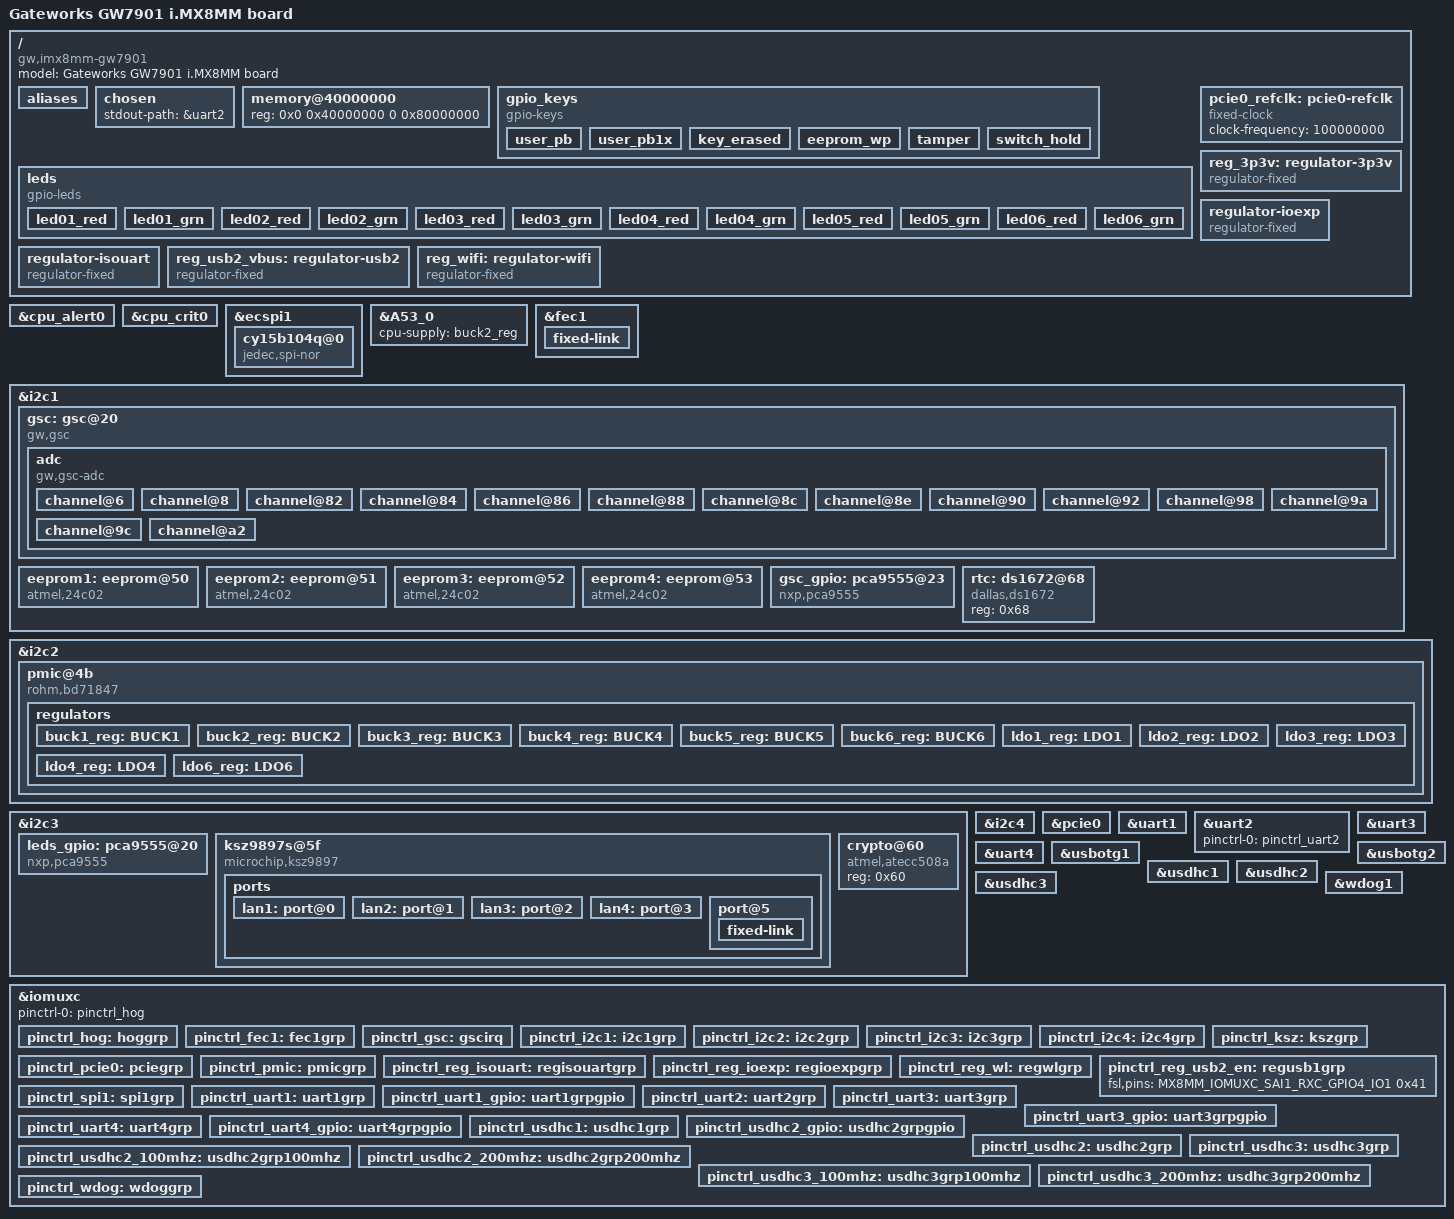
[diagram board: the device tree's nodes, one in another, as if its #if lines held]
// SPDX-License-Identifier: (GPL-2.0+ OR MIT)
/*
 * Copyright 2020 Gateworks Corporation
 */

/dts-v1/;

#include <dt-bindings/usb/pd.h>
#include <dt-bindings/input/linux-event-codes.h>
#include "imx8mm.dtsi"

/ {
	model = "Gateworks GW7901 i.MX8MM board";
	compatible = "gw,imx8mm-gw7901", "fsl,imx8mm";

	aliases {
		ethernet0 = &fec1;
		ethernet1 = &lan1;
		ethernet2 = &lan2;
		ethernet3 = &lan3;
		ethernet4 = &lan4;
		usb0 = &usbotg1;
		usb1 = &usbotg2;
	};

	chosen {
		stdout-path = &uart2;
	};

	memory@40000000 {
		device_type = "memory";
		reg = <0x0 0x40000000 0 0x80000000>;
	};

	gpio_keys {
		compatible = "gpio-keys";
		#address-cells = <1>;
		#size-cells = <0>;

		user_pb {
			label = "user_pb";
			gpios = <&gsc_gpio 2 GPIO_ACTIVE_LOW>;
			linux,code = <BTN_0>;
		};

		user_pb1x {
			label = "user_pb1x";
			linux,code = <BTN_1>;
			interrupt-parent = <&gsc>;
			interrupts = <0>;
		};

		key_erased {
			label = "key-erased";
			linux,code = <BTN_2>;
			interrupt-parent = <&gsc>;
			interrupts = <1>;
		};

		eeprom_wp {
			label = "eeprom_wp";
			linux,code = <BTN_3>;
			interrupt-parent = <&gsc>;
			interrupts = <2>;
		};

		tamper {
			label = "tamper";
			linux,code = <BTN_4>;
			interrupt-parent = <&gsc>;
			interrupts = <5>;
		};

		switch_hold {
			label = "switch_hold";
			linux,code = <BTN_5>;
			interrupt-parent = <&gsc>;
			interrupts = <7>;
		};
	};

	leds {
		compatible = "gpio-leds";

		led01_red {
			label = "led01_red";
			gpios = <&leds_gpio 0 GPIO_ACTIVE_HIGH>;
			default-state = "off";
		};

		led01_grn {
			label = "led01_grn";
			gpios = <&leds_gpio 1 GPIO_ACTIVE_HIGH>;
			default-state = "off";
		};

		led02_red {
			label = "led02_red";
			gpios = <&leds_gpio 2 GPIO_ACTIVE_HIGH>;
			default-state = "off";
		};

		led02_grn {
			label = "led02_grn";
			gpios = <&leds_gpio 3 GPIO_ACTIVE_HIGH>;
			default-state = "off";
		};

		led03_red {
			label = "led03_red";
			gpios = <&leds_gpio 4 GPIO_ACTIVE_HIGH>;
			default-state = "off";
		};

		led03_grn {
			label = "led03_grn";
			gpios = <&leds_gpio 5 GPIO_ACTIVE_HIGH>;
			default-state = "off";
		};

		led04_red {
			label = "led04_red";
			gpios = <&leds_gpio 8 GPIO_ACTIVE_HIGH>;
			default-state = "off";
		};

		led04_grn {
			label = "led04_grn";
			gpios = <&leds_gpio 9 GPIO_ACTIVE_HIGH>;
			default-state = "off";
		};

		led05_red {
			label = "led05_red";
			gpios = <&leds_gpio 10 GPIO_ACTIVE_HIGH>;
			default-state = "off";
		};

		led05_grn {
			label = "led05_grn";
			gpios = <&leds_gpio 11 GPIO_ACTIVE_HIGH>;
			default-state = "off";
		};

		led06_red {
			label = "led06_red";
			gpios = <&leds_gpio 12 GPIO_ACTIVE_HIGH>;
			default-state = "off";
		};

		led06_grn {
			label = "led06_grn";
			gpios = <&leds_gpio 13 GPIO_ACTIVE_HIGH>;
			default-state = "off";
		};
	};

	pcie0_refclk: pcie0-refclk {
		compatible = "fixed-clock";
		#clock-cells = <0>;
		clock-frequency = <100000000>;
	};

	reg_3p3v: regulator-3p3v {
		compatible = "regulator-fixed";
		regulator-name = "3P3V";
		regulator-min-microvolt = <3300000>;
		regulator-max-microvolt = <3300000>;
		regulator-always-on;
	};

	regulator-ioexp {
		pinctrl-names = "default";
		pinctrl-0 = <&pinctrl_reg_ioexp>;
		compatible = "regulator-fixed";
		regulator-name = "ioexp";
		gpio = <&gpio4 21 GPIO_ACTIVE_HIGH>;
		startup-delay-us = <100>;
		enable-active-high;
		regulator-min-microvolt = <3300000>;
		regulator-max-microvolt = <3300000>;
		regulator-always-on;
	};

	regulator-isouart {
		pinctrl-names = "default";
		pinctrl-0 = <&pinctrl_reg_isouart>;
		compatible = "regulator-fixed";
		regulator-name = "iso_uart";
		gpio = <&gpio1 13 GPIO_ACTIVE_LOW>;
		startup-delay-us = <100>;
		regulator-min-microvolt = <3300000>;
		regulator-max-microvolt = <3300000>;
		regulator-always-on;
	};

	reg_usb2_vbus: regulator-usb2 {
		pinctrl-names = "default";
		pinctrl-0 = <&pinctrl_reg_usb2_en>;
		compatible = "regulator-fixed";
		regulator-name = "usb_usb2_vbus";
		gpio = <&gpio4 1 GPIO_ACTIVE_HIGH>;
		enable-active-high;
		regulator-min-microvolt = <5000000>;
		regulator-max-microvolt = <5000000>;
	};

	reg_wifi: regulator-wifi {
		pinctrl-names = "default";
		pinctrl-0 = <&pinctrl_reg_wl>;
		compatible = "regulator-fixed";
		regulator-name = "wifi";
		gpio = <&gpio4 0 GPIO_ACTIVE_HIGH>;
		startup-delay-us = <100>;
		enable-active-high;
		regulator-min-microvolt = <3300000>;
		regulator-max-microvolt = <3300000>;
	};
};

&cpu_alert0 {
	temperature = <95000>;
	hysteresis = <2000>;
	type = "passive";
};

&cpu_crit0 {
	temperature = <105000>;
	hysteresis = <2000>;
	type = "critical";
};

&ecspi1 {
	pinctrl-names = "default";
	pinctrl-0 = <&pinctrl_spi1>;
	cs-gpios = <&gpio5 9 GPIO_ACTIVE_LOW>;
	status = "okay";

	/* CY15B104Q FRAM:
	 * requires adding to drivers/mtd/spi-nor/spi-nor.c:
	 * { "cy15x104q", INFO(0x7f7f7f, 0, 512 * 1024, 1, SPI_NOR_NO_ERASE) },
	 */
	cy15b104q@0 {
		compatible = "jedec,spi-nor", "cy15x104q";
		reg = <0>;
		spi-max-frequency = <40000000>;
		status = "okay";
	};
};

&A53_0 {
	cpu-supply = <&buck2_reg>;
};

&fec1 {
	pinctrl-names = "default";
	pinctrl-0 = <&pinctrl_fec1>;
	phy-mode = "rgmii-id";
	phy-reset-gpios = <&gpio4 19 GPIO_ACTIVE_LOW>;
	phy-reset-duration = <100>;
	phy-reset-post-delay = <100>;
	status = "okay";
	local-mac-address = [00 00 00 00 00 00];

	fixed-link {
		speed = <1000>;
		full-duplex;
	};
};

&i2c1 {
	clock-frequency = <100000>;
	pinctrl-names = "default";
	pinctrl-0 = <&pinctrl_i2c1>;
	status = "okay";

	gsc: gsc@20 {
		compatible = "gw,gsc";
		reg = <0x20>;
		pinctrl-0 = <&pinctrl_gsc>;
		interrupt-parent = <&gpio2>;
		interrupts = <6 IRQ_TYPE_EDGE_FALLING>;
		/*interrupts = <6 IRQ_TYPE_LEVEL_LOW>;*/
		interrupt-controller;
		#interrupt-cells = <1>;
		#size-cells = <0>;

		adc {
			compatible = "gw,gsc-adc";
			#address-cells = <1>;
			#size-cells = <0>;

			channel@6 {
				gw,mode = <0>;
				reg = <0x06>;
				label = "temp";
			};

			channel@8 {
				gw,mode = <1>;
				reg = <0x08>;
				label = "vdd_bat";
			};

			channel@82 {
				gw,mode = <2>;
				reg = <0x82>;
				label = "vin_aux1";
				gw,voltage-divider-ohms = <22100 1000>;
			};

			channel@84 {
				gw,mode = <2>;
				reg = <0x84>;
				label = "vin_aux2";
				gw,voltage-divider-ohms = <22100 1000>;
			};

			channel@86 {
				gw,mode = <2>;
				reg = <0x86>;
				label = "vdd_vin";
				gw,voltage-divider-ohms = <22100 1000>;
			};

			channel@88 {
				gw,mode = <2>;
				reg = <0x88>;
				label = "vdd_3p3";
				gw,voltage-divider-ohms = <10000 10000>;
			};

			channel@8c {
				gw,mode = <2>;
				reg = <0x8c>;
				label = "vdd_2p5";
				gw,voltage-divider-ohms = <10000 10000>;
			};

			channel@8e {
				gw,mode = <2>;
				reg = <0x8e>;
				label = "vdd_0p95";
			};

			channel@90 {
				gw,mode = <2>;
				reg = <0x90>;
				label = "vdd_soc";
			};

			channel@92 {
				gw,mode = <2>;
				reg = <0x92>;
				label = "vdd_arm";
			};

			channel@98 {
				gw,mode = <2>;
				reg = <0x98>;
				label = "vdd_1p8";
			};

			channel@9a {
				gw,mode = <2>;
				reg = <0x9a>;
				label = "vdd_1p2";
			};

			channel@9c {
				gw,mode = <2>;
				reg = <0x9c>;
				label = "vdd_dram";
			};

			channel@a2 {
				gw,mode = <2>;
				reg = <0xa2>;
				label = "vdd_gsc";
				gw,voltage-divider-ohms = <10000 10000>;
			};
		};
	};

	eeprom1: eeprom@50 {
		compatible = "atmel,24c02";
		reg = <0x50>;
		pagesize = <16>;
	};

	eeprom2: eeprom@51 {
		compatible = "atmel,24c02";
		reg = <0x51>;
		pagesize = <16>;
	};

	eeprom3: eeprom@52 {
		compatible = "atmel,24c02";
		reg = <0x52>;
		pagesize = <16>;
	};

	eeprom4: eeprom@53 {
		compatible = "atmel,24c02";
		reg = <0x53>;
		pagesize = <16>;
	};

	gsc_gpio: pca9555@23 {
		compatible = "nxp,pca9555";
		reg = <0x23>;
		gpio-controller;
		#gpio-cells = <2>;
		interrupt-parent = <&gsc>;
		interrupts = <4>;
	};

	rtc: ds1672@68 {
		compatible = "dallas,ds1672";
		reg = <0x68>;
	};
};

&i2c2 {
	clock-frequency = <400000>;
	pinctrl-names = "default";
	pinctrl-0 = <&pinctrl_i2c2>;
	status = "okay";

	pmic@4b {
		compatible = "rohm,bd71847";
		reg = <0x4b>;
		pinctrl-0 = <&pinctrl_pmic>;
		interrupt-parent = <&gpio3>;
		interrupts = <20 IRQ_TYPE_LEVEL_LOW>;

		regulators {
			/* VDD_SOC: 0.805-0.900V (typ=0.8V) */
			buck1_reg: BUCK1 {
				regulator-name = "BUCK1";
				regulator-min-microvolt = <700000>;
				regulator-max-microvolt = <1300000>;
				regulator-boot-on;
				regulator-always-on;
				regulator-ramp-delay = <1250>;
			};

			/* VDD_ARM: 0.805-1.0V (typ=0.9V) */
			buck2_reg: BUCK2 {
				regulator-name = "BUCK2";
				regulator-min-microvolt = <700000>;
				regulator-max-microvolt = <1300000>;
				regulator-boot-on;
				regulator-always-on;
				regulator-ramp-delay = <1250>;
				rohm,dvs-run-voltage = <1000000>;
				rohm,dvs-idle-voltage = <900000>;
			};

			/* VDD_0P95: 0.805-1.0V (typ=0.9V) */
			buck3_reg: BUCK3 {
				// BUCK5 in datasheet
				regulator-name = "BUCK3";
				regulator-min-microvolt = <700000>;
				regulator-max-microvolt = <1350000>;
				regulator-boot-on;
				regulator-always-on;
			};

			/* VDD_3P3 */
			buck4_reg: BUCK4 {
				// BUCK6 in datasheet
				regulator-name = "BUCK4";
				regulator-min-microvolt = <3000000>;
				regulator-max-microvolt = <3300000>;
				regulator-boot-on;
				regulator-always-on;
			};

			/* VDD_1P8 */
			buck5_reg: BUCK5 {
				// BUCK7 in datasheet
				regulator-name = "BUCK5";
				regulator-min-microvolt = <1605000>;
				regulator-max-microvolt = <1995000>;
				regulator-boot-on;
				regulator-always-on;
			};

			/* VDD_DRAM: typ=1.1V */
			buck6_reg: BUCK6 {
				// BUCK8 in datasheet
				regulator-name = "BUCK6";
				regulator-min-microvolt = <800000>;
				regulator-max-microvolt = <1400000>;
				regulator-boot-on;
				regulator-always-on;
			};

			/* NVCC_SNVS_1P8 */
			ldo1_reg: LDO1 {
				regulator-name = "LDO1";
				regulator-min-microvolt = <3000000>;
				regulator-max-microvolt = <3300000>;
				regulator-boot-on;
				regulator-always-on;
			};

			/* VDD_SNVS_0P8 */
			ldo2_reg: LDO2 {
				regulator-name = "LDO2";
				regulator-min-microvolt = <900000>;
				regulator-max-microvolt = <900000>;
				regulator-boot-on;
				regulator-always-on;
			};

			/* VDDA_1P8 */
			ldo3_reg: LDO3 {
				regulator-name = "LDO3";
				regulator-min-microvolt = <1800000>;
				regulator-max-microvolt = <3300000>;
				regulator-boot-on;
				regulator-always-on;
			};

			/* PMIC_LDO4 */
			ldo4_reg: LDO4 {
				regulator-name = "LDO4";
				regulator-min-microvolt = <900000>;
				regulator-max-microvolt = <1800000>;
				regulator-boot-on;
				regulator-always-on;
			};

			/* PMIC_LD06 */
			ldo6_reg: LDO6 {
				regulator-name = "LDO6";
				regulator-min-microvolt = <900000>;
				regulator-max-microvolt = <1800000>;
				regulator-boot-on;
				regulator-always-on;
			};
		};
	};
};

&i2c3 {
	clock-frequency = <400000>;
	pinctrl-names = "default";
	pinctrl-0 = <&pinctrl_i2c3>;
	status = "okay";

	leds_gpio: pca9555@20 {
		compatible = "nxp,pca9555";
		pinctrl-names = "default";
		reg = <0x20>;
		gpio-controller;
		#gpio-cells = <2>;
	};

	ksz9897s@5f {
		compatible = "microchip,ksz9897"; /* optional: ksz9477, ksz9567 */
		reg = <0x5f>;
		pinctrl-0 = <&pinctrl_ksz>;
		interrupt-parent = <&gpio4>;
		interrupts = <17 IRQ_TYPE_EDGE_FALLING>;
		phy-mode = "rgmii-id";

		ports {
			#address-cells = <1>;
			#size-cells = <0>;
			lan1: port@0 {
				reg = <0>;
				label = "lan1";
				local-mac-address = [00 00 00 00 00 00];
			};
			lan2: port@1 {
				reg = <1>;
				label = "lan2";
				local-mac-address = [00 00 00 00 00 00];
			};
			lan3: port@2 {
				reg = <2>;
				label = "lan3";
				local-mac-address = [00 00 00 00 00 00];
			};
			lan4: port@3 {
				reg = <3>;
				label = "lan4";
				local-mac-address = [00 00 00 00 00 00];
			};
			port@5 {
				reg = <5>;
				label = "cpu";
				ethernet = <&fec1>;
				phy-mode = "rgmii-id";

				fixed-link {
					speed = <1000>;
					full-duplex;
				};
			};
		};
	};

	/* is the ATECC608A compatible with the ATECC508 driver? */
	crypto@60 {
		compatible = "atmel,atecc508a";
		reg = <0x60>;
	};
};

&i2c4 {
	clock-frequency = <400000>;
	pinctrl-names = "default";
	pinctrl-0 = <&pinctrl_i2c4>;
	status = "okay";
};

#ifdef REVB // REVA has bad clkcen
&pcie0 {
	pinctrl-names = "default";
	pinctrl-0 = <&pinctrl_pcie0>;
	reset-gpio = <&gpio5 2 GPIO_ACTIVE_LOW>;
	clocks = <&clk IMX8MM_CLK_PCIE1_ROOT>,
		 <&clk IMX8MM_CLK_PCIE1_AUX>,
		 <&clk IMX8MM_CLK_PCIE1_PHY>,
		 <&pcie0_refclk>;
	clock-names = "pcie", "pcie_aux", "pcie_phy", "pcie_bus";
	ext_osc = <1>;
	status = "okay";
};
#endif

&uart1 {
	pinctrl-names = "default";
	pinctrl-0 = <&pinctrl_uart1>, <&pinctrl_uart1_gpio>;
	uart-has-rtscts;
	rts-gpios = <&gpio1 10 GPIO_ACTIVE_LOW>;
	cts-gpios = <&gpio1 11 GPIO_ACTIVE_LOW>;
	dtr-gpios = <&gpio1 12 GPIO_ACTIVE_LOW>;
	dsr-gpios = <&gpio1 14 GPIO_ACTIVE_LOW>;
	dcd-gpios = <&gpio1 15 GPIO_ACTIVE_LOW>;
	status = "okay";
};

&uart2 { /* console */
	pinctrl-names = "default";
	pinctrl-0 = <&pinctrl_uart2>;
	status = "okay";
};

&uart3 {
	pinctrl-names = "default";
	pinctrl-0 = <&pinctrl_uart3>,<&pinctrl_uart3_gpio>;
	uart-has-rtscts;
	cts-gpios = <&gpio4 10 GPIO_ACTIVE_LOW>;
	rts-gpios = <&gpio4 9 GPIO_ACTIVE_LOW>;
	status = "okay";
};

&uart4 {
	pinctrl-names = "default";
	pinctrl-0 = <&pinctrl_uart4>,<&pinctrl_uart4_gpio>;
	uart-has-rtscts;
	cts-gpios = <&gpio5 11 GPIO_ACTIVE_LOW>;
	rts-gpios = <&gpio5 12 GPIO_ACTIVE_LOW>;
	status = "okay";
};

&usbotg1 {
	dr_mode = "host";
	disable-over-current;
	status = "okay";
};

&usbotg2 {
	dr_mode = "host";
	vbus-supply = <&reg_usb2_vbus>;
	disable-over-current;
	status = "okay";
};

&usdhc1 { /* SDIO WiFi */
	assigned-clocks = <&clk IMX8MM_CLK_USDHC1>;
	assigned-clock-rates = <50000000>;
	pinctrl-names = "default";
	pinctrl-0 = <&pinctrl_usdhc1>;
	bus-width = <4>;
	non-removable;
	vmmc-supply = <&reg_wifi>;
	status = "okay";
};

&usdhc2 { /* microSD */
	assigned-clocks = <&clk IMX8MM_CLK_USDHC2>;
	assigned-clock-rates = <200000000>;
	pinctrl-names = "default", "state_100mhz", "state_200mhz";
	pinctrl-0 = <&pinctrl_usdhc2>,<&pinctrl_usdhc2_gpio>;
	pinctrl-1 = <&pinctrl_usdhc2_100mhz>,<&pinctrl_usdhc2_gpio>;
	pinctrl-2 = <&pinctrl_usdhc2_200mhz>,<&pinctrl_usdhc2_gpio>;
	cd-gpios = <&gpio2 12 GPIO_ACTIVE_LOW>;
	bus-width = <4>;
	vmmc-supply = <&reg_3p3v>;
#ifndef REVB  // next-rev
	no-1-8-v;
#endif
	status = "okay";
};

&usdhc3 { /* eMMC */
	assigned-clocks = <&clk IMX8MM_CLK_USDHC3_ROOT>;
	assigned-clock-rates = <400000000>;
	pinctrl-names = "default", "state_100mhz", "state_200mhz";
	pinctrl-0 = <&pinctrl_usdhc3>;
	pinctrl-1 = <&pinctrl_usdhc3_100mhz>;
	pinctrl-2 = <&pinctrl_usdhc3_200mhz>;
	bus-width = <8>;
	non-removable;
	status = "okay";
};

&wdog1 {
	pinctrl-names = "default";
	pinctrl-0 = <&pinctrl_wdog>;
	fsl,ext-reset-output;
	status = "okay";
};

&iomuxc {
	pinctrl-names = "default";
	pinctrl-0 = <&pinctrl_hog>;

	pinctrl_hog: hoggrp {
		fsl,pins = <
			/* Isolated Digital IO */
			MX8MM_IOMUXC_SPDIF_TX_GPIO5_IO3		0x40000041 /* DIG2_OUT */
			MX8MM_IOMUXC_SPDIF_RX_GPIO5_IO4		0x40000041 /* DIG2_IN */
			MX8MM_IOMUXC_GPIO1_IO08_GPIO1_IO8	0x40000041 /* DIG1_IN */
			MX8MM_IOMUXC_GPIO1_IO09_GPIO1_IO9	0x40000041 /* DIG1_OUT */
			/* Misc */
			MX8MM_IOMUXC_SAI3_RXD_GPIO4_IO30	0x40000041 /* SIM2DET# */
			MX8MM_IOMUXC_SAI3_RXC_GPIO4_IO29	0x40000041 /* SIM1DET# */
			MX8MM_IOMUXC_SPDIF_EXT_CLK_GPIO5_IO5	0x40000041 /* SIMSEL# */
#ifndef REVB // REVA has bad clkcen
			/* PCIe */
			MX8MM_IOMUXC_SAI3_TXFS_GPIO4_IO31	0x40000041 /* WDIS# */
			MX8MM_IOMUXC_SAI3_MCLK_GPIO5_IO2	0x40000041 /* PERST# */
#endif
		>;
	};

	pinctrl_fec1: fec1grp {
		fsl,pins = <
			MX8MM_IOMUXC_ENET_MDC_ENET1_MDC			0x3
			MX8MM_IOMUXC_ENET_MDIO_ENET1_MDIO		0x3
			MX8MM_IOMUXC_ENET_TD3_ENET1_RGMII_TD3		0x1f
			MX8MM_IOMUXC_ENET_TD2_ENET1_RGMII_TD2		0x1f
			MX8MM_IOMUXC_ENET_TD1_ENET1_RGMII_TD1		0x1f
			MX8MM_IOMUXC_ENET_TD0_ENET1_RGMII_TD0		0x1f
			MX8MM_IOMUXC_ENET_RD3_ENET1_RGMII_RD3		0x91
			MX8MM_IOMUXC_ENET_RD2_ENET1_RGMII_RD2		0x91
			MX8MM_IOMUXC_ENET_RD1_ENET1_RGMII_RD1		0x91
			MX8MM_IOMUXC_ENET_RD0_ENET1_RGMII_RD0		0x91
			MX8MM_IOMUXC_ENET_TXC_ENET1_RGMII_TXC		0x1f
			MX8MM_IOMUXC_ENET_RXC_ENET1_RGMII_RXC		0x91
			MX8MM_IOMUXC_ENET_RX_CTL_ENET1_RGMII_RX_CTL	0x91
			MX8MM_IOMUXC_ENET_TX_CTL_ENET1_RGMII_TX_CTL	0x1f
			MX8MM_IOMUXC_SAI1_TXD6_GPIO4_IO18		0x19 /* ENET_IRQ# */
			MX8MM_IOMUXC_SAI1_TXD7_GPIO4_IO19		0x19 /* ENET_RST# */
		>;
	};

	pinctrl_gsc: gscirq {
		fsl,pins = <
			MX8MM_IOMUXC_SD1_DATA4_GPIO2_IO6	0x159
		>;
	};

	pinctrl_i2c1: i2c1grp {
		fsl,pins = <
			MX8MM_IOMUXC_I2C1_SCL_I2C1_SCL		0x400001c3
			MX8MM_IOMUXC_I2C1_SDA_I2C1_SDA		0x400001c3
		>;
	};

	pinctrl_i2c2: i2c2grp {
		fsl,pins = <
			MX8MM_IOMUXC_I2C2_SCL_I2C2_SCL		0x400001c3
			MX8MM_IOMUXC_I2C2_SDA_I2C2_SDA		0x400001c3
		>;
	};

	pinctrl_i2c3: i2c3grp {
		fsl,pins = <
			MX8MM_IOMUXC_I2C3_SCL_I2C3_SCL		0x400001c3
			MX8MM_IOMUXC_I2C3_SDA_I2C3_SDA		0x400001c3
		>;
	};

	pinctrl_i2c4: i2c4grp {
		fsl,pins = <
			MX8MM_IOMUXC_I2C4_SCL_I2C4_SCL		0x400001c3
			MX8MM_IOMUXC_I2C4_SDA_I2C4_SDA		0x400001c3
		>;
	};

	pinctrl_ksz: kszgrp {
		fsl,pins = <
			MX8MM_IOMUXC_SAI1_TXD5_GPIO4_IO17	0x41 /* IRQ# */
			MX8MM_IOMUXC_SAI1_TXD6_GPIO4_IO18	0x41 /* RST# */
		>;
	};

#ifdef REVB // REVA has bad clkcen
	pinctrl_pcie0: pciegrp {
		fsl,pins = <
			MX8MM_IOMUXC_SAI3_TXFS_GPIO4_IO31	0x40000041 /* WDIS# */
			MX8MM_IOMUXC_SAI3_MCLK_GPIO5_IO2	0x40000041 /* PERST# */
		>;
	};
#endif

	pinctrl_pmic: pmicgrp {
		fsl,pins = <
			MX8MM_IOMUXC_SAI5_RXC_GPIO3_IO20	0x41 /* IRQ# */
		>;
	};

	pinctrl_reg_isouart: regisouartgrp {
		fsl,pins = <
			MX8MM_IOMUXC_GPIO1_IO13_GPIO1_IO13	0x40000041
		>;
	};

	pinctrl_reg_ioexp: regioexpgrp {
		fsl,pins = <
			MX8MM_IOMUXC_SAI2_RXFS_GPIO4_IO21	0x40000041
		>;
	};

	pinctrl_reg_wl: regwlgrp {
		fsl,pins = <
			MX8MM_IOMUXC_SAI1_RXFS_GPIO4_IO0	0x40000041
		>;
	};

	pinctrl_reg_usb2_en: regusb1grp {
		fsl,pins = <
			MX8MM_IOMUXC_SAI1_RXC_GPIO4_IO1		0x41
		>;
	};

	pinctrl_spi1: spi1grp {
		fsl,pins = <
			MX8MM_IOMUXC_ECSPI1_SCLK_ECSPI1_SCLK	0x82
			MX8MM_IOMUXC_ECSPI1_MOSI_ECSPI1_MOSI	0x82
			MX8MM_IOMUXC_ECSPI1_MISO_ECSPI1_MISO	0x82
			MX8MM_IOMUXC_ECSPI1_SS0_GPIO5_IO9	0x140
		>;
	};

	pinctrl_uart1: uart1grp {
		fsl,pins = <
			MX8MM_IOMUXC_UART1_RXD_UART1_DCE_RX	0x140
			MX8MM_IOMUXC_UART1_TXD_UART1_DCE_TX	0x140
			MX8MM_IOMUXC_GPIO1_IO10_GPIO1_IO10	0x140 /* RTS */
			MX8MM_IOMUXC_GPIO1_IO11_GPIO1_IO11	0x140 /* CTS */
		>;
	};

	pinctrl_uart1_gpio: uart1grpgpio {
		fsl,pins = <
			MX8MM_IOMUXC_GPIO1_IO03_GPIO1_IO3	0x40000041 /* RS232# */
#ifndef REVB
			MX8MM_IOMUXC_GPIO1_IO04_GPIO1_IO4	0x40000041 /* RS485# */
#endif
			MX8MM_IOMUXC_GPIO1_IO05_GPIO1_IO5	0x40000041 /* RS422# */
			MX8MM_IOMUXC_GPIO1_IO12_GPIO1_IO12	0x41 /* DTR */
			MX8MM_IOMUXC_GPIO1_IO14_GPIO1_IO14	0x41 /* DSR */
			MX8MM_IOMUXC_GPIO1_IO15_GPIO1_IO15	0x41 /* DCD */
		>;
	};

	pinctrl_uart2: uart2grp {
		fsl,pins = <
			MX8MM_IOMUXC_UART2_RXD_UART2_DCE_RX	0x140
			MX8MM_IOMUXC_UART2_TXD_UART2_DCE_TX	0x140
		>;
	};

	pinctrl_uart3: uart3grp {
		fsl,pins = <
			MX8MM_IOMUXC_UART3_RXD_UART3_DCE_RX	0x140
			MX8MM_IOMUXC_UART3_TXD_UART3_DCE_TX	0x140
			MX8MM_IOMUXC_SAI1_RXD7_GPIO4_IO9	0x140 /* RTS */
			MX8MM_IOMUXC_SAI1_TXFS_GPIO4_IO10	0x140 /* CTS */
		>;
	};

	pinctrl_uart3_gpio: uart3grpgpio {
		fsl,pins = <
			MX8MM_IOMUXC_SAI1_RXD4_GPIO4_IO6	0x40000041 /* RS232# */
			MX8MM_IOMUXC_SAI1_RXD5_GPIO4_IO7	0x40000041 /* RS422# */
			MX8MM_IOMUXC_SAI1_RXD6_GPIO4_IO8	0x40000041 /* RS485# */
		>;
	};

	pinctrl_uart4: uart4grp {
		fsl,pins = <
			MX8MM_IOMUXC_UART4_RXD_UART4_DCE_RX	0x140
			MX8MM_IOMUXC_UART4_TXD_UART4_DCE_TX	0x140
			MX8MM_IOMUXC_ECSPI2_MOSI_GPIO5_IO11	0x140 /* CTS */
			MX8MM_IOMUXC_ECSPI2_MISO_GPIO5_IO12	0x140 /* RTS */
		>;
	};

	pinctrl_uart4_gpio: uart4grpgpio {
		fsl,pins = <

			MX8MM_IOMUXC_ECSPI2_SCLK_GPIO5_IO10	0x40000041 /* RS232# */
			MX8MM_IOMUXC_ECSPI2_SS0_GPIO5_IO13	0x40000041 /* RS422# */
			MX8MM_IOMUXC_SAI2_MCLK_GPIO4_IO27	0x40000041 /* RS485# */
		>;
	};

	pinctrl_usdhc1: usdhc1grp {
		fsl,pins = <
			MX8MM_IOMUXC_SD1_CLK_USDHC1_CLK		0x190
			MX8MM_IOMUXC_SD1_CMD_USDHC1_CMD		0x1d0
			MX8MM_IOMUXC_SD1_DATA0_USDHC1_DATA0	0x1d0
			MX8MM_IOMUXC_SD1_DATA1_USDHC1_DATA1	0x1d0
			MX8MM_IOMUXC_SD1_DATA2_USDHC1_DATA2	0x1d0
			MX8MM_IOMUXC_SD1_DATA3_USDHC1_DATA3	0x1d0
		>;
	};

	pinctrl_usdhc2_gpio: usdhc2grpgpio {
		fsl,pins = <
			MX8MM_IOMUXC_SD2_CD_B_GPIO2_IO12        0x1c4
#ifdef REVB  // next-rev
			MX8MM_IOMUXC_GPIO1_IO04_USDHC2_VSELECT	0x1d0
#endif
		>;
	};

	pinctrl_usdhc2: usdhc2grp {
		fsl,pins = <
			MX8MM_IOMUXC_SD2_CLK_USDHC2_CLK		0x190
			MX8MM_IOMUXC_SD2_CMD_USDHC2_CMD		0x1d0
			MX8MM_IOMUXC_SD2_DATA0_USDHC2_DATA0	0x1d0
			MX8MM_IOMUXC_SD2_DATA1_USDHC2_DATA1	0x1d0
			MX8MM_IOMUXC_SD2_DATA2_USDHC2_DATA2	0x1d0
			MX8MM_IOMUXC_SD2_DATA3_USDHC2_DATA3	0x1d0
		>;
	};

	pinctrl_usdhc2_100mhz: usdhc2grp100mhz {
		fsl,pins = <
			MX8MM_IOMUXC_SD2_CLK_USDHC2_CLK		0x194
			MX8MM_IOMUXC_SD2_CMD_USDHC2_CMD		0x1d4
			MX8MM_IOMUXC_SD2_DATA0_USDHC2_DATA0	0x1d4
			MX8MM_IOMUXC_SD2_DATA1_USDHC2_DATA1	0x1d4
			MX8MM_IOMUXC_SD2_DATA2_USDHC2_DATA2	0x1d4
			MX8MM_IOMUXC_SD2_DATA3_USDHC2_DATA3	0x1d4
		>;
	};

	pinctrl_usdhc2_200mhz: usdhc2grp200mhz {
		fsl,pins = <
			MX8MM_IOMUXC_SD2_CLK_USDHC2_CLK		0x196
			MX8MM_IOMUXC_SD2_CMD_USDHC2_CMD		0x1d6
			MX8MM_IOMUXC_SD2_DATA0_USDHC2_DATA0	0x1d6
			MX8MM_IOMUXC_SD2_DATA1_USDHC2_DATA1	0x1d6
			MX8MM_IOMUXC_SD2_DATA2_USDHC2_DATA2	0x1d6
			MX8MM_IOMUXC_SD2_DATA3_USDHC2_DATA3	0x1d6
		>;
	};

	pinctrl_usdhc3: usdhc3grp {
		fsl,pins = <
			MX8MM_IOMUXC_NAND_WE_B_USDHC3_CLK	0x190
			MX8MM_IOMUXC_NAND_WP_B_USDHC3_CMD	0x1d0
			MX8MM_IOMUXC_NAND_DATA04_USDHC3_DATA0	0x1d0
			MX8MM_IOMUXC_NAND_DATA05_USDHC3_DATA1	0x1d0
			MX8MM_IOMUXC_NAND_DATA06_USDHC3_DATA2	0x1d0
			MX8MM_IOMUXC_NAND_DATA07_USDHC3_DATA3	0x1d0
			MX8MM_IOMUXC_NAND_RE_B_USDHC3_DATA4	0x1d0
			MX8MM_IOMUXC_NAND_CE2_B_USDHC3_DATA5	0x1d0
			MX8MM_IOMUXC_NAND_CE3_B_USDHC3_DATA6	0x1d0
			MX8MM_IOMUXC_NAND_CLE_USDHC3_DATA7	0x1d0
			MX8MM_IOMUXC_NAND_CE1_B_USDHC3_STROBE 	0x190
		>;
	};

	pinctrl_usdhc3_100mhz: usdhc3grp100mhz {
		fsl,pins = <
			MX8MM_IOMUXC_NAND_WE_B_USDHC3_CLK	0x194
			MX8MM_IOMUXC_NAND_WP_B_USDHC3_CMD	0x1d4
			MX8MM_IOMUXC_NAND_DATA04_USDHC3_DATA0	0x1d4
			MX8MM_IOMUXC_NAND_DATA05_USDHC3_DATA1	0x1d4
			MX8MM_IOMUXC_NAND_DATA06_USDHC3_DATA2	0x1d4
			MX8MM_IOMUXC_NAND_DATA07_USDHC3_DATA3	0x1d4
			MX8MM_IOMUXC_NAND_RE_B_USDHC3_DATA4	0x1d4
			MX8MM_IOMUXC_NAND_CE2_B_USDHC3_DATA5	0x1d4
			MX8MM_IOMUXC_NAND_CE3_B_USDHC3_DATA6	0x1d4
			MX8MM_IOMUXC_NAND_CLE_USDHC3_DATA7	0x1d4
			MX8MM_IOMUXC_NAND_CE1_B_USDHC3_STROBE 	0x194
		>;
	};

	pinctrl_usdhc3_200mhz: usdhc3grp200mhz {
		fsl,pins = <
			MX8MM_IOMUXC_NAND_WE_B_USDHC3_CLK	0x196
			MX8MM_IOMUXC_NAND_WP_B_USDHC3_CMD	0x1d6
			MX8MM_IOMUXC_NAND_DATA04_USDHC3_DATA0	0x1d6
			MX8MM_IOMUXC_NAND_DATA05_USDHC3_DATA1	0x1d6
			MX8MM_IOMUXC_NAND_DATA06_USDHC3_DATA2	0x1d6
			MX8MM_IOMUXC_NAND_DATA07_USDHC3_DATA3	0x1d6
			MX8MM_IOMUXC_NAND_RE_B_USDHC3_DATA4	0x1d6
			MX8MM_IOMUXC_NAND_CE2_B_USDHC3_DATA5	0x1d6
			MX8MM_IOMUXC_NAND_CE3_B_USDHC3_DATA6	0x1d6
			MX8MM_IOMUXC_NAND_CLE_USDHC3_DATA7	0x1d6
			MX8MM_IOMUXC_NAND_CE1_B_USDHC3_STROBE 	0x196
		>;
	};

	pinctrl_wdog: wdoggrp {
		fsl,pins = <
			MX8MM_IOMUXC_GPIO1_IO02_WDOG1_WDOG_B	0xc6
		>;
	};
};
